# ESP32 register map
Vendor: ESPRESSIF SYSTEMS (SHANGHAI) CO., LTD.; Series: ESP32 Series; File version: 17
CPU: Xtensa LX6 r0p0, little endian, no MPU, FPU, 0 interrupt priority bits
Address unit: 32 bits
Registers are 32-bit, read-write, reset 0x0 unless marked. A register's access mark holds for its fields unless they carry their own. Offsets are from the block's base; [hi:lo] are bit positions; {n}, {i} and the like mark numbered series.

## SENS — SENS Peripheral
Base 0x3FF48800
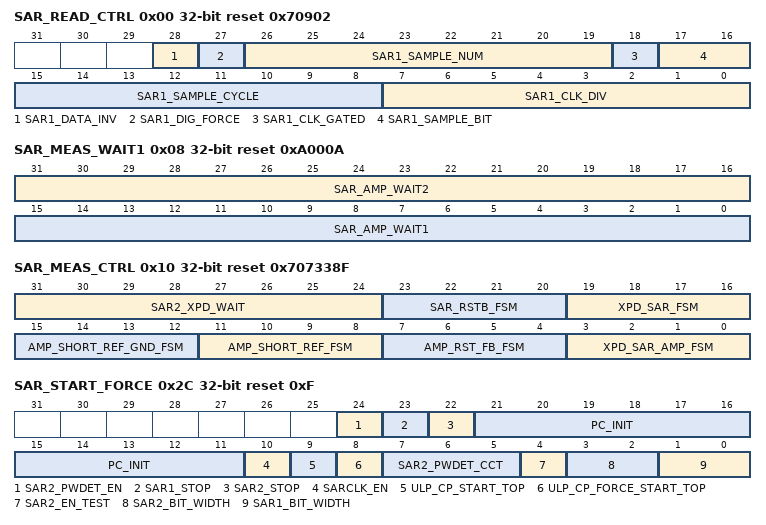
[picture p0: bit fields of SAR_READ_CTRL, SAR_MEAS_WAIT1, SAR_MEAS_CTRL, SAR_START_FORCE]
0x00 SAR_READ_CTRL reset 0x70902
  [28] SAR1_DATA_INV — Invert SAR ADC1 data
  [27] SAR1_DIG_FORCE — 1: SAR ADC1 controlled by DIG ADC1 CTRL 0: SAR ADC1 controlled by RTC ADC1 CTRL
  [26:19] SAR1_SAMPLE_NUM
  [18] SAR1_CLK_GATED
  [17:16] SAR1_SAMPLE_BIT — 00: for 9-bit width 01: for 10-bit width 10: for 11-bit width 11: for 12-bit width
  [15:8] SAR1_SAMPLE_CYCLE — sample cycles for SAR ADC1
  [7:0] SAR1_CLK_DIV — clock divider
0x04 SAR_READ_STATUS1 ro
  [31:0] SAR1_READER_STATUS
0x08 SAR_MEAS_WAIT1 reset 0xA000A
  [31:16] SAR_AMP_WAIT2, [15:0] SAR_AMP_WAIT1
0x0C SAR_MEAS_WAIT2 reset 0x20000A
  [27:20] SAR2_RSTB_WAIT, [19:18] FORCE_XPD_SAR, [17:16] FORCE_XPD_AMP, [0] FORCE_XPD_SAR_SW, [15:0] SAR_AMP_WAIT3
0x10 SAR_MEAS_CTRL reset 0x707338F
  [31:24] SAR2_XPD_WAIT, [23:20] SAR_RSTB_FSM, [19:16] XPD_SAR_FSM, [15:12] AMP_SHORT_REF_GND_FSM, [11:8] AMP_SHORT_REF_FSM, [7:4] AMP_RST_FB_FSM, [3:0] XPD_SAR_AMP_FSM
0x14 SAR_READ_STATUS2 ro
  [31:0] SAR2_READER_STATUS
0x18 ULP_CP_SLEEP_CYC0 reset 0xC8
  [31:0] SLEEP_CYCLES_S0 — sleep cycles for ULP-coprocessor timer
0x1C ULP_CP_SLEEP_CYC1 reset 0x64
  [31:0] SLEEP_CYCLES_S1
0x20 ULP_CP_SLEEP_CYC2 reset 0x32
  [31:0] SLEEP_CYCLES_S2
0x24 ULP_CP_SLEEP_CYC3 reset 0x28
  [31:0] SLEEP_CYCLES_S3
0x28 ULP_CP_SLEEP_CYC4 reset 0x14
  [31:0] SLEEP_CYCLES_S4
0x2C SAR_START_FORCE reset 0xF
  [24] SAR2_PWDET_EN
  [23] SAR1_STOP — stop SAR ADC1 conversion
  [22] SAR2_STOP — stop SAR ADC2 conversion
  [21:11] PC_INIT — initialized PC for ULP-coprocessor
  [10] SARCLK_EN
  [9] ULP_CP_START_TOP — Write 1 to start ULP-coprocessor only active when reg_ulp_cp_force_start_top = 1
  [8] ULP_CP_FORCE_START_TOP — 1: ULP-coprocessor is started by SW 0: ULP-coprocessor is started by timer
  [7:5] SAR2_PWDET_CCT — SAR2_PWDET_CCT PA power detector capacitance tuning.
  [4] SAR2_EN_TEST — SAR2_EN_TEST only active when reg_sar2_dig_force = 0
  [3:2] SAR2_BIT_WIDTH — 00: 9 bit 01: 10 bits 10: 11bits 11: 12bits
  [1:0] SAR1_BIT_WIDTH — 00: 9 bit 01: 10 bits 10: 11bits 11: 12bits
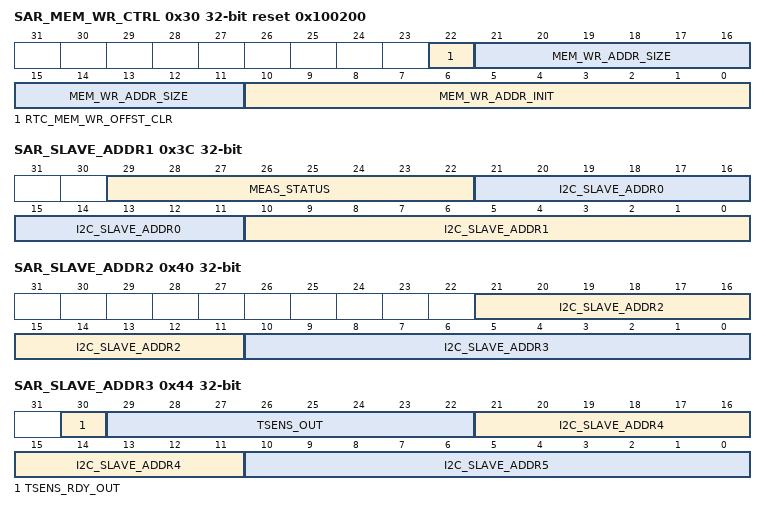
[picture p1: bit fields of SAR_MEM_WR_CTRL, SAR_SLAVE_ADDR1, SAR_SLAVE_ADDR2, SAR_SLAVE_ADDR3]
0x30 SAR_MEM_WR_CTRL access per field reset 0x100200
  [22] RTC_MEM_WR_OFFST_CLR wo, [21:11] MEM_WR_ADDR_SIZE rw, [10:0] MEM_WR_ADDR_INIT rw
0x34 SAR_ATTEN1 reset 0xFFFFFFFF
  [31:0] SAR1_ATTEN — 2-bit attenuation for each pad 11:1dB 10:6dB 01:3dB 00:0dB
0x38 SAR_ATTEN2 reset 0xFFFFFFFF
  [31:0] SAR2_ATTEN — 2-bit attenuation for each pad 11:1dB 10:6dB 01:3dB 00:0dB
0x3C SAR_SLAVE_ADDR1 access per field
  [29:22] MEAS_STATUS ro, [21:11] I2C_SLAVE_ADDR0 rw, [10:0] I2C_SLAVE_ADDR1 rw
0x40 SAR_SLAVE_ADDR2
  [21:11] I2C_SLAVE_ADDR2, [10:0] I2C_SLAVE_ADDR3
0x44 SAR_SLAVE_ADDR3 access per field
  [30] TSENS_RDY_OUT ro — indicate temperature sensor out ready
  [29:22] TSENS_OUT ro — temperature sensor data out
  [21:11] I2C_SLAVE_ADDR4 rw
  [10:0] I2C_SLAVE_ADDR5 rw
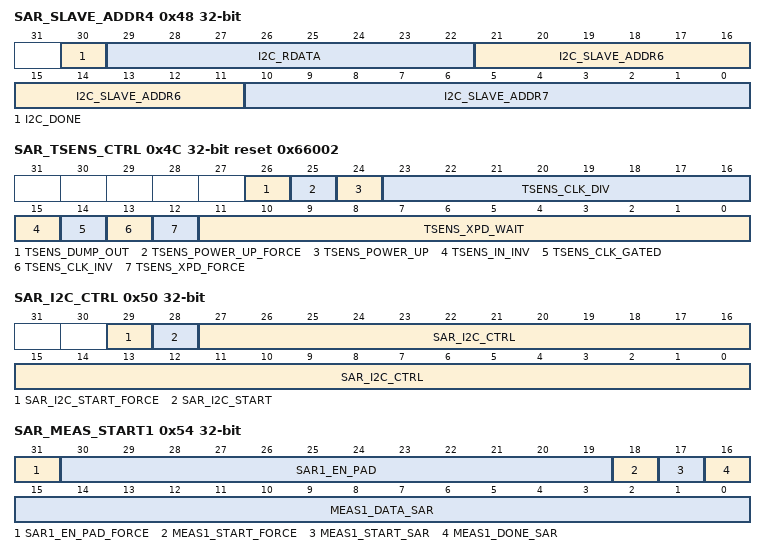
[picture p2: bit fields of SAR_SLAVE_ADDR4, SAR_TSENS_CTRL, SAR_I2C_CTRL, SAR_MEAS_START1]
0x48 SAR_SLAVE_ADDR4 access per field
  [30] I2C_DONE ro — indicate I2C done
  [29:22] I2C_RDATA ro — I2C read data
  [21:11] I2C_SLAVE_ADDR6 rw
  [10:0] I2C_SLAVE_ADDR7 rw
0x4C SAR_TSENS_CTRL reset 0x66002
  [26] TSENS_DUMP_OUT — temperature sensor dump out only active when reg_tsens_power_up_force = 1
  [25] TSENS_POWER_UP_FORCE — 1: dump out & power up controlled by SW 0: by FSM
  [24] TSENS_POWER_UP — temperature sensor power up
  [23:16] TSENS_CLK_DIV — temperature sensor clock divider
  [15] TSENS_IN_INV — invert temperature sensor data
  [14] TSENS_CLK_GATED
  [13] TSENS_CLK_INV
  [12] TSENS_XPD_FORCE
  [11:0] TSENS_XPD_WAIT
0x50 SAR_I2C_CTRL
  [29] SAR_I2C_START_FORCE — 1: I2C started by SW 0: I2C started by FSM
  [28] SAR_I2C_START — start I2C only active when reg_sar_i2c_start_force = 1
  [27:0] SAR_I2C_CTRL — I2C control data only active when reg_sar_i2c_start_force = 1
0x54 SAR_MEAS_START1 access per field
  [31] SAR1_EN_PAD_FORCE rw — 1: SAR ADC1 pad enable bitmap is controlled by SW 0: SAR ADC1 pad enable bitmap is controlled by ULP-coprocessor
  [30:19] SAR1_EN_PAD rw — SAR ADC1 pad enable bitmap only active when reg_sar1_en_pad_force = 1
  [18] MEAS1_START_FORCE rw — 1: SAR ADC1 controller (in RTC) is started by SW 0: SAR ADC1 controller is started by ULP-coprocessor
  [17] MEAS1_START_SAR rw — SAR ADC1 controller (in RTC) starts conversion only active when reg_meas1_start_force = 1
  [16] MEAS1_DONE_SAR ro — SAR ADC1 conversion done indication
  [15:0] MEAS1_DATA_SAR ro — SAR ADC1 data
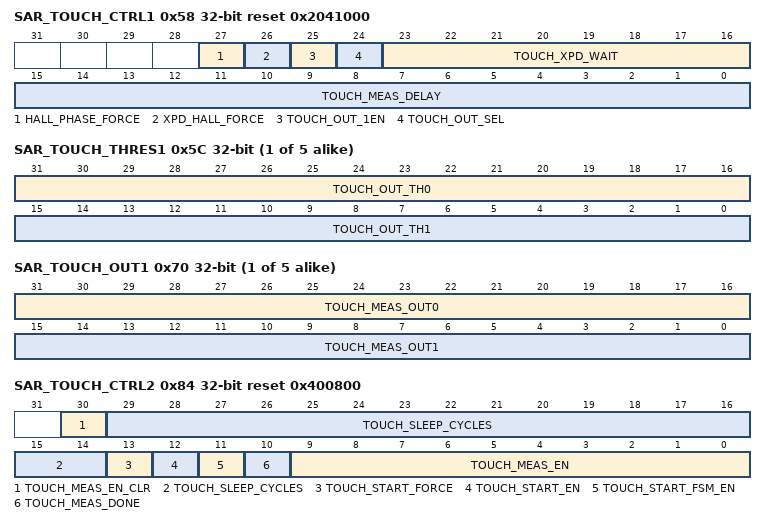
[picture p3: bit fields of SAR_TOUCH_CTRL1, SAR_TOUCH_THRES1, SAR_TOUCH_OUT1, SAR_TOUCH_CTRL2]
0x58 SAR_TOUCH_CTRL1 reset 0x2041000
  [27] HALL_PHASE_FORCE — 1: HALL PHASE is controlled by SW 0: HALL PHASE is controlled by FSM in ULP-coprocessor
  [26] XPD_HALL_FORCE — 1: XPD HALL is controlled by SW. 0: XPD HALL is controlled by FSM in ULP-coprocessor
  [25] TOUCH_OUT_1EN — 1: wakeup interrupt is generated if SET1 is "touched" 0: wakeup interrupt is generated only if SET1 & SET2 is both "touched"
  [24] TOUCH_OUT_SEL — 1: when the counter is greater then the threshold the touch pad is considered as "touched" 0: when the counter is less than the threshold the touch pad is considered as "touched"
  [23:16] TOUCH_XPD_WAIT — the waiting cycles (in 8MHz) between TOUCH_START and TOUCH_XPD
  [15:0] TOUCH_MEAS_DELAY — the meas length (in 8MHz)
{0x58+4i} SAR_TOUCH_THRES{i} (i=1..5)
  [31:16] TOUCH_OUT_TH{2i-2} — the threshold for touch pad {2i-2}
  [15:0] TOUCH_OUT_TH{2i-1} — the threshold for touch pad {2i-1}
{0x6C+4i} SAR_TOUCH_OUT{i} ro (i=1..5)
  [31:16] TOUCH_MEAS_OUT{2i-2} — the counter for touch pad {2i-2}
  [15:0] TOUCH_MEAS_OUT{2i-1} — the counter for touch pad {2i-1}
0x84 SAR_TOUCH_CTRL2 access per field reset 0x400800
  [30] TOUCH_MEAS_EN_CLR wo — to clear reg_touch_meas_en
  [29:14] TOUCH_SLEEP_CYCLES rw — sleep cycles for timer
  [13] TOUCH_START_FORCE rw — 1: to start touch fsm by SW 0: to start touch fsm by timer
  [12] TOUCH_START_EN rw — 1: start touch fsm valid when reg_touch_start_force is set
  [11] TOUCH_START_FSM_EN rw — 1: TOUCH_START & TOUCH_XPD is controlled by touch fsm 0: TOUCH_START & TOUCH_XPD is controlled by registers
  [10] TOUCH_MEAS_DONE ro — fsm set 1 to indicate touch touch meas is done
  [9:0] TOUCH_MEAS_EN ro — 10-bit register to indicate which pads are "touched"
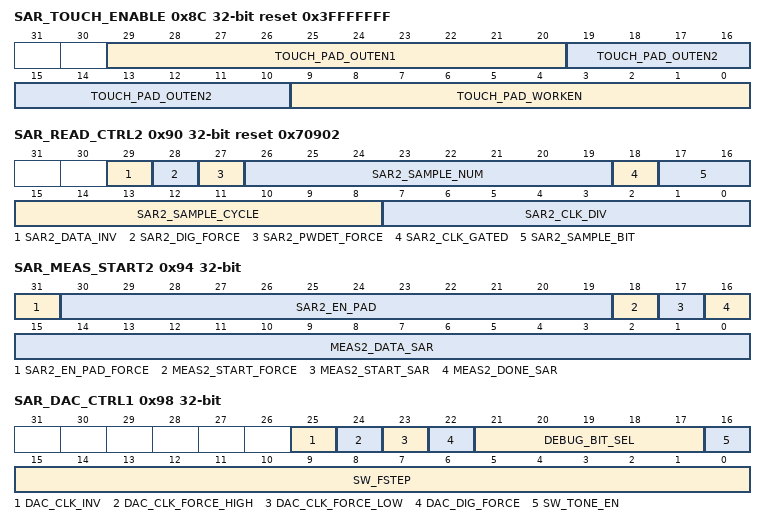
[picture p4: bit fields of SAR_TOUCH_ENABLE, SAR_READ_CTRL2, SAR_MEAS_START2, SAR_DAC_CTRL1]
0x8C SAR_TOUCH_ENABLE reset 0x3FFFFFFF
  [29:20] TOUCH_PAD_OUTEN1 — Bitmap defining SET1 for generating wakeup interrupt. SET1 is "touched" only if at least one of touch pad in SET1 is "touched".
  [19:10] TOUCH_PAD_OUTEN2 — Bitmap defining SET2 for generating wakeup interrupt. SET2 is "touched" only if at least one of touch pad in SET2 is "touched".
  [9:0] TOUCH_PAD_WORKEN — Bitmap defining the working set during the measurement.
0x90 SAR_READ_CTRL2 reset 0x70902
  [29] SAR2_DATA_INV — Invert SAR ADC2 data
  [28] SAR2_DIG_FORCE — 1: SAR ADC2 controlled by DIG ADC2 CTRL or PWDET CTRL 0: SAR ADC2 controlled by RTC ADC2 CTRL
  [27] SAR2_PWDET_FORCE
  [26:19] SAR2_SAMPLE_NUM
  [18] SAR2_CLK_GATED
  [17:16] SAR2_SAMPLE_BIT — 00: for 9-bit width 01: for 10-bit width 10: for 11-bit width 11: for 12-bit width
  [15:8] SAR2_SAMPLE_CYCLE — sample cycles for SAR ADC2
  [7:0] SAR2_CLK_DIV — clock divider
0x94 SAR_MEAS_START2 access per field
  [31] SAR2_EN_PAD_FORCE rw — 1: SAR ADC2 pad enable bitmap is controlled by SW 0: SAR ADC2 pad enable bitmap is controlled by ULP-coprocessor
  [30:19] SAR2_EN_PAD rw — SAR ADC2 pad enable bitmap only active when reg_sar2_en_pad_force = 1
  [18] MEAS2_START_FORCE rw — 1: SAR ADC2 controller (in RTC) is started by SW 0: SAR ADC2 controller is started by ULP-coprocessor
  [17] MEAS2_START_SAR rw — SAR ADC2 controller (in RTC) starts conversion only active when reg_meas2_start_force = 1
  [16] MEAS2_DONE_SAR ro — SAR ADC2 conversion done indication
  [15:0] MEAS2_DATA_SAR ro — SAR ADC2 data
0x98 SAR_DAC_CTRL1
  [25] DAC_CLK_INV — 1: invert PDAC_CLK
  [24] DAC_CLK_FORCE_HIGH — 1: force PDAC_CLK to high
  [23] DAC_CLK_FORCE_LOW — 1: force PDAC_CLK to low
  [22] DAC_DIG_FORCE — 1: DAC1 & DAC2 use DMA 0: DAC1 & DAC2 do not use DMA
  [21:17] DEBUG_BIT_SEL
  [16] SW_TONE_EN — 1: enable CW generator 0: disable CW generator
  [15:0] SW_FSTEP — frequency step for CW generator can be used to adjust the frequency
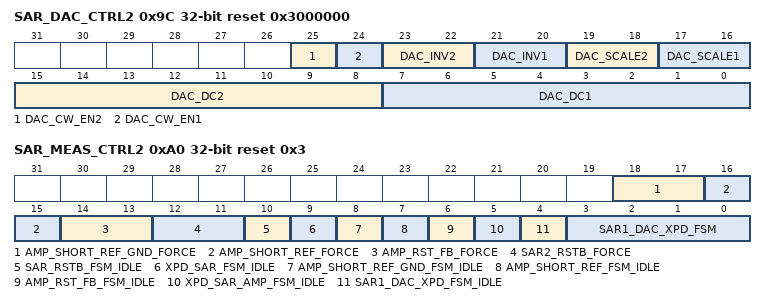
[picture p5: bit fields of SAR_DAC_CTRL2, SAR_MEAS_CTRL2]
0x9C SAR_DAC_CTRL2 reset 0x3000000
  [25] DAC_CW_EN2 — 1: to select CW generator as source to PDAC2_DAC[7:0] 0: to select register reg_pdac2_dac[7:0] as source to PDAC2_DAC[7:0]
  [24] DAC_CW_EN1 — 1: to select CW generator as source to PDAC1_DAC[7:0] 0: to select register reg_pdac1_dac[7:0] as source to PDAC1_DAC[7:0]
  [23:22] DAC_INV2 — 00: do not invert any bits 01: invert all bits 10: invert MSB 11: invert all bits except MSB
  [21:20] DAC_INV1 — 00: do not invert any bits 01: invert all bits 10: invert MSB 11: invert all bits except MSB
  [19:18] DAC_SCALE2 — 00: no scale 01: scale to 1/2 10: scale to 1/4 scale to 1/8
  [17:16] DAC_SCALE1 — 00: no scale 01: scale to 1/2 10: scale to 1/4 scale to 1/8
  [15:8] DAC_DC2 — DC offset for DAC2 CW generator
  [7:0] DAC_DC1 — DC offset for DAC1 CW generator
0xA0 SAR_MEAS_CTRL2 reset 0x3
  [18:17] AMP_SHORT_REF_GND_FORCE, [16:15] AMP_SHORT_REF_FORCE, [14:13] AMP_RST_FB_FORCE, [12:11] SAR2_RSTB_FORCE, [10] SAR_RSTB_FSM_IDLE, [9] XPD_SAR_FSM_IDLE, [8] AMP_SHORT_REF_GND_FSM_IDLE, [7] AMP_SHORT_REF_FSM_IDLE, [6] AMP_RST_FB_FSM_IDLE, [5] XPD_SAR_AMP_FSM_IDLE, [4] SAR1_DAC_XPD_FSM_IDLE, [3:0] SAR1_DAC_XPD_FSM
0xF8 SAR_NOUSE
0xFC SARDATE reset 0x1605180
  [27:0] SAR_DATE
